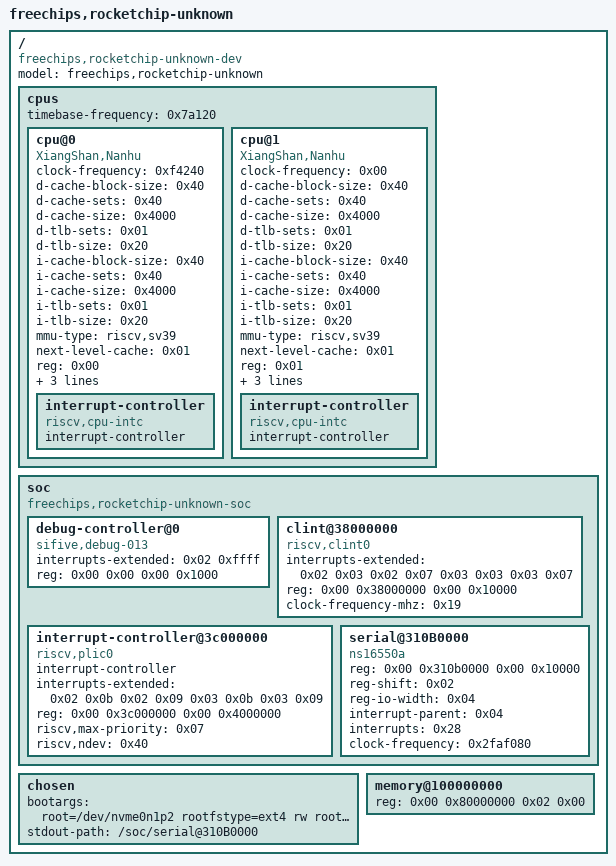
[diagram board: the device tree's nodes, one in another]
/dts-v1/;

/ {
	#address-cells = <0x02>;
	#size-cells = <0x02>;
	compatible = "freechips,rocketchip-unknown-dev";
	model = "freechips,rocketchip-unknown";

	cpus {
		#address-cells = <0x01>;
		#size-cells = <0x00>;
		timebase-frequency = <0x7a120>;

		cpu@0 {
			clock-frequency = <0xf4240>;
			compatible = "XiangShan,Nanhu", "riscv";
			d-cache-block-size = <0x40>;
			d-cache-sets = <0x40>;
			d-cache-size = <0x4000>;
			d-tlb-sets = <0x01>;
			d-tlb-size = <0x20>;
			device_type = "cpu";
			i-cache-block-size = <0x40>;
			i-cache-sets = <0x40>;
			i-cache-size = <0x4000>;
			i-tlb-sets = <0x01>;
			i-tlb-size = <0x20>;
			mmu-type = "riscv,sv39";
			next-level-cache = <0x01>;
			reg = <0x00>;
			riscv,isa = "rv64imafdc";
			status = "okay";
			timebase-frequency = <0x7a120>;
			tlb-split;

			interrupt-controller {
				#interrupt-cells = <0x01>;
				compatible = "riscv,cpu-intc";
				interrupt-controller;
				phandle = <0x02>;
			};
		};

		cpu@1 {
			clock-frequency = <0x00>;
			compatible = "XiangShan,Nanhu", "riscv";
			d-cache-block-size = <0x40>;
			d-cache-sets = <0x40>;
			d-cache-size = <0x4000>;
			d-tlb-sets = <0x01>;
			d-tlb-size = <0x20>;
			device_type = "cpu";
			i-cache-block-size = <0x40>;
			i-cache-sets = <0x40>;
			i-cache-size = <0x4000>;
			i-tlb-sets = <0x01>;
			i-tlb-size = <0x20>;
			mmu-type = "riscv,sv39";
			next-level-cache = <0x01>;
			reg = <0x01>;
			riscv,isa = "rv64imafdc";
			status = "okay";
			timebase-frequency = <0x7a120>;
			tlb-split;

			interrupt-controller {
				#interrupt-cells = <0x01>;
				compatible = "riscv,cpu-intc";
				interrupt-controller;
				phandle = <0x03>;
			};
		};
	};

	soc {
		#address-cells = <0x02>;
		#size-cells = <0x02>;
		compatible = "freechips,rocketchip-unknown-soc", "simple-bus";
		ranges;

		debug-controller@0 {
			compatible = "sifive,debug-013", "riscv,debug-013";
			interrupts-extended = <0x02 0xffff>;
			reg = <0x00 0x00 0x00 0x1000>;
			reg-names = "control";
		};

		clint@38000000 {
			compatible = "riscv,clint0";
			interrupts-extended = <0x02 0x03 0x02 0x07 0x03 0x03 0x03 0x07>;
			reg = <0x00 0x38000000 0x00 0x10000>;
			reg-names = "control";
			clock-frequency-mhz = <0x19>;
		};

		interrupt-controller@3c000000 {
			#interrupt-cells = <0x01>;
			compatible = "riscv,plic0";
			interrupt-controller;
			interrupts-extended = <0x02 0x0b 0x02 0x09 0x03 0x0b 0x03 0x09>;
			reg = <0x00 0x3c000000 0x00 0x4000000>;
			reg-names = "control";
			riscv,max-priority = <0x07>;
			riscv,ndev = <0x40>;
			phandle = <0x04>;
		};

		serial@310B0000 {
			compatible = "ns16550a";
			reg = <0x00 0x310b0000 0x00 0x10000>;
			reg-shift = <0x02>;
			reg-io-width = <0x04>;
			interrupt-parent = <0x04>;
			interrupts = <0x28>;
			clock-frequency = <0x2faf080>;
			status = "okay";
		};
	};

	chosen {
		bootargs = "root=/dev/nvme0n1p2 rootfstype=ext4 rw rootwait console=ttyS0,115200n8 earlycon=sbi noinitrd";
		stdout-path = "/soc/serial@310B0000";
	};

	memory@100000000 {
		device_type = "memory";
		reg = <0x00 0x80000000 0x02 0x00>;
		phandle = <0x01>;
	};
};
